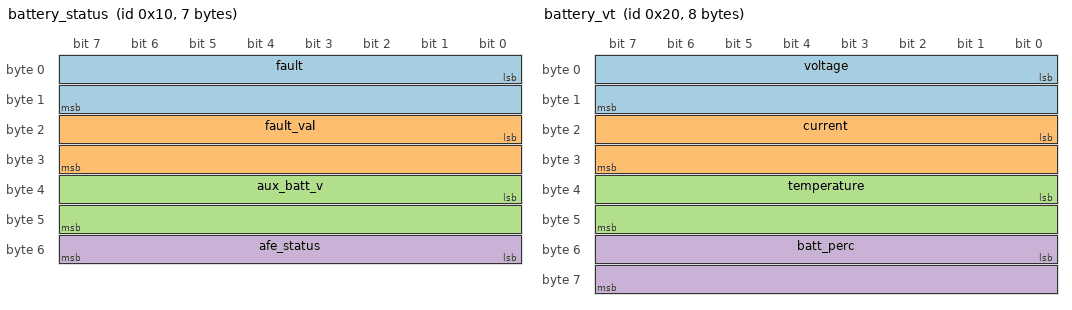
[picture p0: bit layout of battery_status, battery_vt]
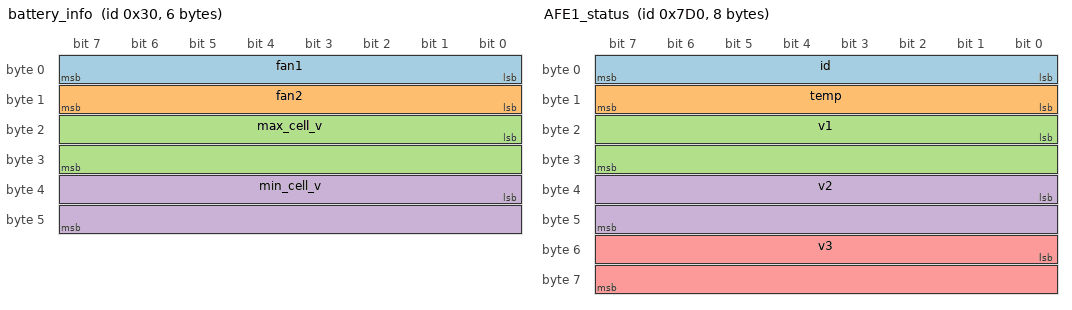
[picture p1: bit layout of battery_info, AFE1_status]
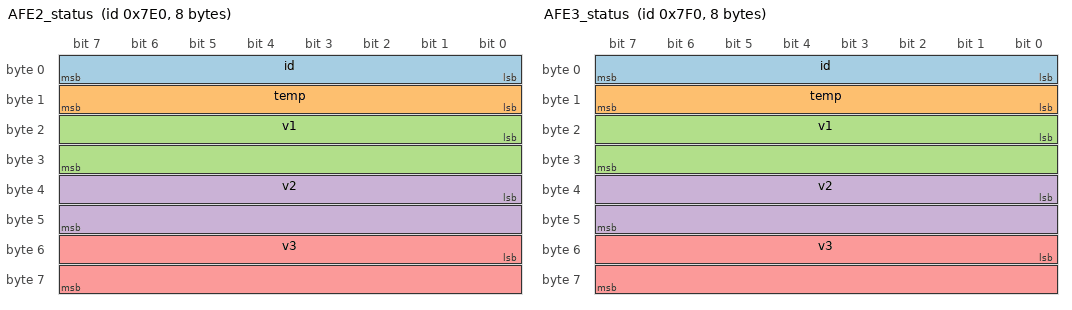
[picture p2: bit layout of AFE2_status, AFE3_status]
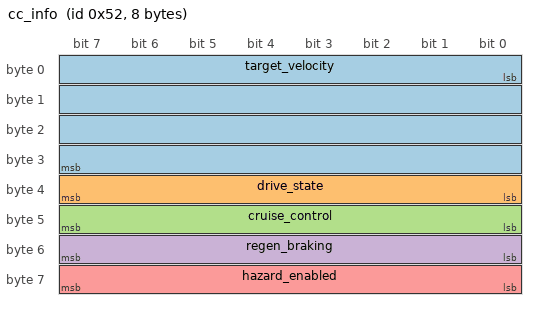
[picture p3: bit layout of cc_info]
NS_ :

BS_:

BU_: BMS_CARRIER CAN_COMMUNICATION CENTRE_CONSOLE

BO_  16  battery_status: 7 bms_carrier
  SG_ fault : 0|16@1+ (1,0) [0|65535] "" centre_console, power_distribution
  SG_ fault_val : 16|16@1+ (1,0) [0|65535] "" centre_console, power_distribution
  SG_ aux_batt_v : 32|16@1+ (1,0) [0|65535] "" centre_console, power_distribution
  SG_ afe_status : 48|8@1+ (1,0) [0|255] "" centre_console, power_distribution

BO_  32  battery_vt: 8 bms_carrier
  SG_ voltage : 0|16@1+ (1,0) [0|65535] "" centre_console
  SG_ current : 16|16@1+ (1,0) [0|65535] "" centre_console
  SG_ temperature : 32|16@1+ (1,0) [0|65535] "" centre_console
  SG_ batt_perc : 48|16@1+ (1,0) [0|65535] "" centre_console

BO_  48  battery_info: 6 bms_carrier
  SG_ fan1 : 0|8@1+ (1,0) [0|255] "" centre_console
  SG_ fan2 : 8|8@1+ (1,0) [0|255] "" centre_console
  SG_ max_cell_v : 16|16@1+ (1,0) [0|65535] "" centre_console
  SG_ min_cell_v : 32|16@1+ (1,0) [0|65535] "" centre_console

BO_   2000 AFE1_status: 8 bms_carrier
  SG_ id : 0|8@1+ (1,0) [0|255] "" centre_console, power_distribution
  SG_ temp : 8|8@1+ (1,0) [0|255] "" centre_console, power_distribution
  SG_ v1 : 16|16@1+ (1,0) [0|65535] "" centre_console, power_distribution
  SG_ v2 : 32|16@1+ (1,0) [0|65535] "" centre_console, power_distribution
  SG_ v3 : 48|16@1+ (1,0) [0|65535] "" centre_console, power_distribution

BO_   2016 AFE2_status: 8 bms_carrier
  SG_ id : 0|8@1+ (1,0) [0|255] "" centre_console, power_distribution
  SG_ temp : 8|8@1+ (1,0) [0|255] "" centre_console, power_distribution
  SG_ v1 : 16|16@1+ (1,0) [0|65535] "" centre_console, power_distribution
  SG_ v2 : 32|16@1+ (1,0) [0|65535] "" centre_console, power_distribution
  SG_ v3 : 48|16@1+ (1,0) [0|65535] "" centre_console, power_distribution

BO_   2032 AFE3_status: 8 bms_carrier
  SG_ id : 0|8@1+ (1,0) [0|255] "" centre_console, power_distribution
  SG_ temp : 8|8@1+ (1,0) [0|255] "" centre_console, power_distribution
  SG_ v1 : 16|16@1+ (1,0) [0|65535] "" centre_console, power_distribution
  SG_ v2 : 32|16@1+ (1,0) [0|65535] "" centre_console, power_distribution
  SG_ v3 : 48|16@1+ (1,0) [0|65535] "" centre_console, power_distribution

BO_   1953 fast_one_shot_msg: 4 can_communication
  SG_ sig1 : 0|16@1+ (1,0) [0|65535] "" can_communication
  SG_ sig2 : 16|16@1+ (1,0) [0|65535] "" can_communication

BO_   1969 medium_one_shot_msg: 4 can_communication
  SG_ sig1 : 0|16@1+ (1,0) [0|65535] "" can_communication
  SG_ sig2 : 16|16@1+ (1,0) [0|65535] "" can_communication

BO_   1985 slow_one_shot_msg: 4 can_communication
  SG_ sig1 : 0|16@1+ (1,0) [0|65535] "" can_communication
  SG_ sig2 : 16|16@1+ (1,0) [0|65535] "" can_communication

BO_  66  cc_pedal: 5 centre_console
  SG_ throttle_output : 0|32@1+ (1,0) [0|4294967295] "" motor_controller, power_distribution
  SG_ brake_output : 32|8@1+ (1,0) [0|255] "" motor_controller, power_distribution

BO_  82  cc_info: 8 centre_console
  SG_ target_velocity : 0|32@1+ (1,0) [0|4294967295] "" motor_controller, power_distribution
  SG_ drive_state : 32|8@1+ (1,0) [0|255] "" motor_controller, power_distribution
  SG_ cruise_control : 40|8@1+ (1,0) [0|255] "" motor_controller, power_distribution
  SG_ regen_braking : 48|8@1+ (1,0) [0|255] "" motor_controller, power_distribution
  SG_ hazard_enabled : 56|8@1+ (1,0) [0|255] "" motor_controller, power_distribution

BO_  98  cc_steering: 2 centre_console
  SG_ input_cc : 0|8@1+ (1,0) [0|255] "" power_distribution, motor_controller
  SG_ input_lights : 8|8@1+ (1,0) [0|255] "" power_distribution, motor_controller

BO_  114  cc_regen_percentage: 4 centre_console
  SG_ percent : 0|32@1+ (1,0) [0|4294967295] "" motor_controller
